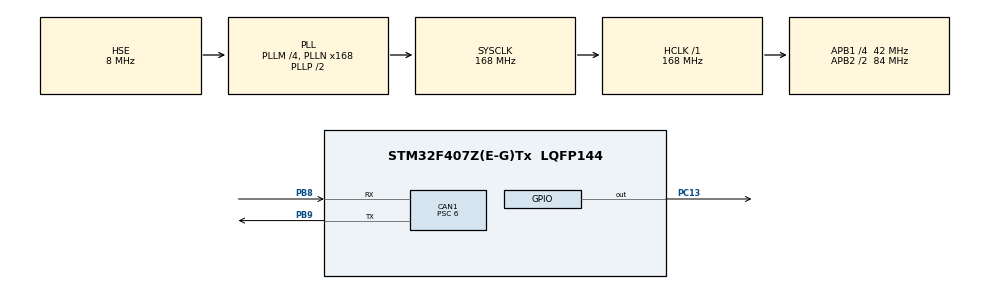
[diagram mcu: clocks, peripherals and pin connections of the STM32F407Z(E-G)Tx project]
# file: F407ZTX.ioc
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CAN1.ABOM=ENABLE
CAN1.BS1=CAN_BS1_11TQ
CAN1.BS2=CAN_BS2_2TQ
CAN1.CalculateBaudRate=500000
CAN1.CalculateTimeBit=2000
CAN1.CalculateTimeQuantum=142.85714285714286
CAN1.Mode=CAN_MODE_NORMAL
CAN1.NART=ENABLE
CAN1.Prescaler=6
Mcu.Family=STM32F4
Mcu.Name=STM32F407Z(E-G)Tx
Mcu.Package=LQFP144
NVIC.CAN1_RX0_IRQn=true\:0\:0\:false\:false\:true\:true\:true\:true
NVIC.PriorityGroup=NVIC_PRIORITYGROUP_4
PA13.Mode=Serial_Wire
PA13.Signal=SYS_JTMS-SWDIO
PA14.Mode=Serial_Wire
PA14.Signal=SYS_JTCK-SWCLK
PB8.Mode=CAN_Activate
PB8.Signal=CAN1_RX
PB9.Mode=CAN_Activate
PB9.Signal=CAN1_TX
PC13-ANTI_TAMP.Signal=GPIO_Output
PH0-OSC_IN.Mode=HSE-External-Oscillator
PH0-OSC_IN.Signal=RCC_OSC_IN
PH1-OSC_OUT.Mode=HSE-External-Oscillator
PH1-OSC_OUT.Signal=RCC_OSC_OUT
ProjectManager.HeapSize=0x200
ProjectManager.StackSize=0x400
ProjectManager.TargetToolchain=MDK-ARM V5.32
RCC.48MHZClocksFreq_Value=84000000
RCC.AHBFreq_Value=168000000
RCC.APB1CLKDivider=RCC_HCLK_DIV4
RCC.APB1Freq_Value=42000000
RCC.APB1TimFreq_Value=84000000
RCC.APB2CLKDivider=RCC_HCLK_DIV2
RCC.APB2Freq_Value=84000000
RCC.APB2TimFreq_Value=168000000
RCC.CortexFreq_Value=168000000
RCC.HCLKFreq_Value=168000000
RCC.HSE_VALUE=8000000
RCC.HSI_VALUE=16000000
RCC.LSE_VALUE=32768
RCC.PLLM=4
RCC.PLLN=168
RCC.PLLSourceVirtual=RCC_PLLSOURCE_HSE
RCC.SYSCLKFreq_VALUE=168000000
RCC.SYSCLKSource=RCC_SYSCLKSOURCE_PLLCLK
RCC.VCOOutputFreq_Value=336000000
board=custom

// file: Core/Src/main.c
/* USER CODE BEGIN Header */
/**
  ******************************************************************************
  * @file           : main.c
  * @brief          : Main program body
  ******************************************************************************
  * @attention
  *
  * Copyright (c) 2026 STMicroelectronics.
  * All rights reserved.
  *
  * This software is licensed under terms that can be found in the LICENSE file
  * in the root directory of this software component.
  * If no LICENSE file comes with this software, it is provided AS-IS.
  *
  ******************************************************************************
  */
/* USER CODE END Header */
#include "main.h"
#include "can.h"
#include "gpio.h"

/* USER CODE BEGIN Includes */
#include "stdio.h"
/* USER CODE END Includes */

/* USER CODE BEGIN PV */
CAN_TxHeaderTypeDef TxHeader;
uint8_t TxData[8] = {0x11, 0x22, 0x33, 0x44, 0x55, 0x66, 0x77, 0x88};
uint32_t TxMailbox;

// ⚠️ 新增：接收变量
CAN_RxHeaderTypeDef RxHeader;
uint8_t RxData[8];
/* USER CODE END PV */

void SystemClock_Config(void);

int main(void)
{

  /* MCU Configuration--------------------------------------------------------*/

  /* Reset of all peripherals, Initializes the Flash interface and the Systick. */
  HAL_Init();

  /* Configure the system clock */
  SystemClock_Config();

  /* Initialize all configured peripherals */
  MX_GPIO_Init();
  MX_CAN1_Init();
  /* USER CODE BEGIN 2 */
    CAN_FilterTypeDef sFilterConfig;
  sFilterConfig.FilterBank = 0;
  sFilterConfig.FilterMode = CAN_FILTERMODE_IDMASK;
  sFilterConfig.FilterScale = CAN_FILTERSCALE_32BIT;
  sFilterConfig.FilterIdHigh = 0x0000;
  sFilterConfig.FilterIdLow = 0x0000;
  sFilterConfig.FilterMaskIdHigh = 0x0000;
  sFilterConfig.FilterMaskIdLow = 0x0000;
  sFilterConfig.FilterFIFOAssignment = CAN_RX_FIFO0;
  sFilterConfig.FilterActivation = ENABLE;
  sFilterConfig.SlaveStartFilterBank = 14;
  HAL_CAN_ConfigFilter(&hcan1, &sFilterConfig);

  // 2. 启动 CAN 并开启接收中断
  HAL_CAN_Start(&hcan1);
  HAL_CAN_ActivateNotification(&hcan1, CAN_IT_RX_FIFO0_MSG_PENDING);
  /* USER CODE END 2 */

  /* Infinite loop */
  while (1)
  {

    /* USER CODE BEGIN 3 */
    HAL_GPIO_TogglePin(GPIOC, GPIO_PIN_13); // 正常翻转一次

    // ⚠️ 重点修改：给 TxData[0] 赋值为 50，代表 50% 的速度
    TxData[0] = 50;

    TxHeader.StdId = 0x123;
    TxHeader.ExtId = 0;
    TxHeader.IDE = CAN_ID_STD;
    TxHeader.RTR = CAN_RTR_DATA;
    TxHeader.DLC = 8;
    TxHeader.TransmitGlobalTime = DISABLE;

    // 记录发送状态
    HAL_StatusTypeDef status = HAL_ERROR;
    if (HAL_CAN_GetTxMailboxesFreeLevel(&hcan1) > 0)
    {
        status = HAL_CAN_AddTxMessage(&hcan1, &TxHeader, TxData, &TxMailbox);
    }

    // 灵魂测试：如果发送成功（F103收到并回了ACK），连闪三次！
    if (status == HAL_OK) {
        for(int i=0; i<6; i++) {
            HAL_GPIO_TogglePin(GPIOC, GPIO_PIN_13);
            HAL_Delay(100);
        }
    }

    HAL_Delay(1000); // 改为1秒发一次，方便观察
  }
  /* USER CODE END 3 */
}

void SystemClock_Config(void)
{
  RCC_OscInitTypeDef RCC_OscInitStruct = {0};
  RCC_ClkInitTypeDef RCC_ClkInitStruct = {0};

  /** Configure the main internal regulator output voltage
  */
  __HAL_RCC_PWR_CLK_ENABLE();
  __HAL_PWR_VOLTAGESCALING_CONFIG(PWR_REGULATOR_VOLTAGE_SCALE1);

  /** Initializes the RCC Oscillators according to the specified parameters
  * in the RCC_OscInitTypeDef structure.
  */
  RCC_OscInitStruct.OscillatorType = RCC_OSCILLATORTYPE_HSE;
  RCC_OscInitStruct.HSEState = RCC_HSE_ON;
  RCC_OscInitStruct.PLL.PLLState = RCC_PLL_ON;
  RCC_OscInitStruct.PLL.PLLSource = RCC_PLLSOURCE_HSE;
  RCC_OscInitStruct.PLL.PLLM = 4;
  RCC_OscInitStruct.PLL.PLLN = 168;
  RCC_OscInitStruct.PLL.PLLP = RCC_PLLP_DIV2;
  RCC_OscInitStruct.PLL.PLLQ = 4;
  if (HAL_RCC_OscConfig(&RCC_OscInitStruct) != HAL_OK)
  {
    Error_Handler();
  }

  /** Initializes the CPU, AHB and APB buses clocks
  */
  RCC_ClkInitStruct.ClockType = RCC_CLOCKTYPE_HCLK|RCC_CLOCKTYPE_SYSCLK
                              |RCC_CLOCKTYPE_PCLK1|RCC_CLOCKTYPE_PCLK2;
  RCC_ClkInitStruct.SYSCLKSource = RCC_SYSCLKSOURCE_PLLCLK;
  RCC_ClkInitStruct.AHBCLKDivider = RCC_SYSCLK_DIV1;
  RCC_ClkInitStruct.APB1CLKDivider = RCC_HCLK_DIV4;
  RCC_ClkInitStruct.APB2CLKDivider = RCC_HCLK_DIV2;

  if (HAL_RCC_ClockConfig(&RCC_ClkInitStruct, FLASH_LATENCY_5) != HAL_OK)
  {
    Error_Handler();
  }
}

/* USER CODE BEGIN 4 */
// CAN 接收中断回调函数
// F407 接收中断回调函数
void HAL_CAN_RxFifo0MsgPendingCallback(CAN_HandleTypeDef *hcan)
{
    if (HAL_CAN_GetRxMessage(hcan, CAN_RX_FIFO0, &RxHeader, RxData) == HAL_OK)
    {
        // ⚠️ 中断里绝对不要用 printf！只翻转灯或置标志位即可
        HAL_GPIO_TogglePin(GPIOC, GPIO_PIN_13);
    }
}
/* USER CODE END 4 */

void Error_Handler(void)
{
  __disable_irq();
  while (1)
  {
  }
}
